# haltium_celldsp register map
Vendor: Nordic Semiconductor; Series: nRFHaltium; File version: 1
Registers are 32-bit, read-write, reset 0x0 unless marked. A register's access mark holds for its fields unless they carry their own. Offsets are from the block's base; [hi:lo] are bit positions; lines under a group give offsets from that group; {n}, {i} and the like mark numbered series.

## GLOBAL_TSGEN — GENERIC 0
Base 0xBF041000
Same registers: GENERIC2 0x45007000, GLOBAL_CAN 0x4F8D5000, GLOBAL_ETB 0xBF044000, GLOBAL_ETR 0xBF045000
0x00 TASKS_GENERICTASK wo — Generic event
  [0] TASKS_GENERICTASK
    1=Trigger task
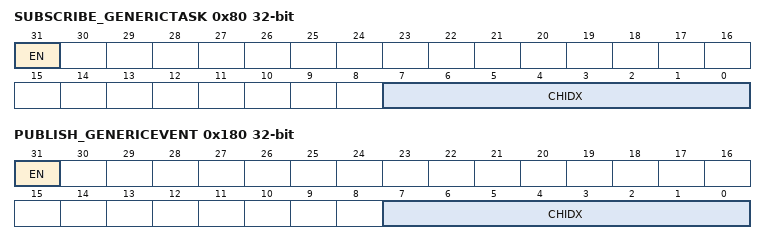
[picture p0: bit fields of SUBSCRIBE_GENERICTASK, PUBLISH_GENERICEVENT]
0x80 SUBSCRIBE_GENERICTASK — Subscribe configuration for task GENERICTASK
  [31] EN
    0=Disabled (Disable subscription); 1=Enabled (Enable subscription)
  [7:0] CHIDX — DPPI channel that task GENERICTASK will subscribe to
0x100 EVENTS_GENERICEVENT — Generic event
  [0] EVENTS_GENERICEVENT
    0=NotGenerated (Event not generated); 1=Generated (Event generated)
0x180 PUBLISH_GENERICEVENT — Publish configuration for event GENERICEVENT
  [31] EN
    0=Disabled (Disable publishing); 1=Enabled (Enable publishing)
  [7:0] CHIDX — DPPI channel that event GENERICEVENT will publish to
0x300 INTEN — Enable or disable interrupt
  [0] GENERICEVENT — Enable or disable interrupt for event GENERICEVENT
    0=Disabled; 1=Enabled
0x304 INTENSET — Enable interrupt
  [0] GENERICEVENT — Write '1' to enable interrupt for event GENERICEVENT
    on read: 0=Disabled (Read: Disabled); 1=Enabled (Read: Enabled) | on write: 1=Set (Enable)
0x308 INTENCLR — Disable interrupt
  [0] GENERICEVENT — Write '1' to disable interrupt for event GENERICEVENT
    on read: 0=Disabled (Read: Disabled); 1=Enabled (Read: Enabled) | on write: 1=Clear (Disable)

## RAMC00 — RAM Controller 0
Base 0x45004000
Same registers: RAMC10 0x45005000, RAMC20 0x45006000
0x300 INTEN — Enable or disable interrupt
0x304 INTENSET — Enable interrupt
0x308 INTENCLR — Disable interrupt
0x500 WAITSTATES — Waitstates for read.
  [2:0] WAITSTATES — Waitstates for read from RAM or ROM.
0x600 SECBASE — Base address for secure access area.
  [31:0] ADDR — Base address
0x604 SECENABLE — Enable secure access restrictions.
  [0] ENABLE — Enable secure access restrictions
    0=Disable (Secure access restrictions disabled); 1=Enable (Secure access restrictions enabled)

## DSPINTMAP — DSP interrupt mapper
Base 0x45008000
0x504 OFFSET reset 0x100000 — Address offset for IRQ destination address
0x508 ADDRESSINCREMENT reset 0x200 — Address increment for IRQ destination address
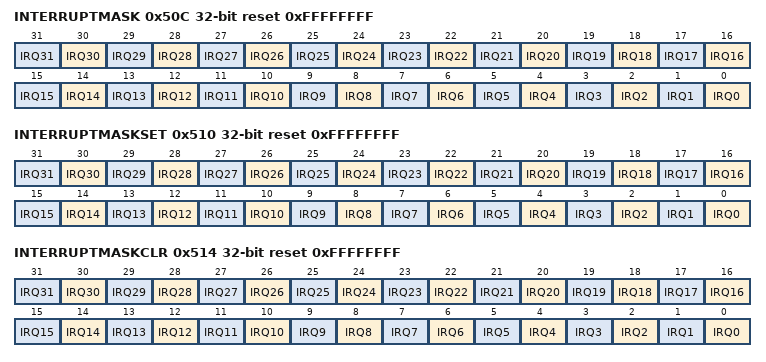
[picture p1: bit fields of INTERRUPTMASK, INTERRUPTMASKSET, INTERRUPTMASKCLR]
0x50C INTERRUPTMASK reset 0xFFFFFFFF — Write interrupt mask
  [all] fields
    0=Low (IRQ[i] is unmasked); 1=High (IRQ[i] is masked)
  [n] IRQ{n} (n=0..31) — Mask or unmask interrupt IRQ[i]
0x510 INTERRUPTMASKSET reset 0xFFFFFFFF write-1-sets — Set individual mask bits in interrupt mask
  [n] IRQ{n} (n=0..31) — Write '1' to mask IRQ[i]
    on read: 0=Low (Read: IRQ{n} is unmasked); 1=High (Read: IRQ{n} is masked) | on write: 1=Set (Write: writing a '1' sets the mask on; writing a '0' has no effect)
0x514 INTERRUPTMASKCLR reset 0xFFFFFFFF write-1-clears — Clear individual mask bits in interrupt mask
  [n] IRQ{n} (n=0..31) — Write '1' to unmask IRQ[i]
    on read: 0=Low (Read: IRQ{n} is unmasked); 1=High (Read: IRQ{n} is masked) | on write: 1=Clear (Write: writing a '1' sets the mask off; writing a '0' has no effect)
{0x518+4i} INTERRUPTPRIORITY[{i}] (i=0..31) — Description collection: Priority of interrupt IRQn
  [2:0] PRIORITY — Interrupt priority
    0=Highest priority; 7=Lowest priority
0xD00 INTERRUPTSTATUS ro — InterruptStatus indicates that an IRQ is sent to DSP, but not yet cleared

## PPIB0 — PPIB APB registers 0
Base 0x4500E000
Same registers: PPIB1 0x45016000
{0x0+4i} TASKS_SEND[{i}] (i=0..31) wo — Description collection: This task is unused, but the PPIB provides the SUBSCRIBE task to connect SEND [n] task.
  [0] TASKS_SEND — This task is unused, but the PPIB provides the SUBSCRIBE task to connect SEND [n] task.
    1=Trigger task
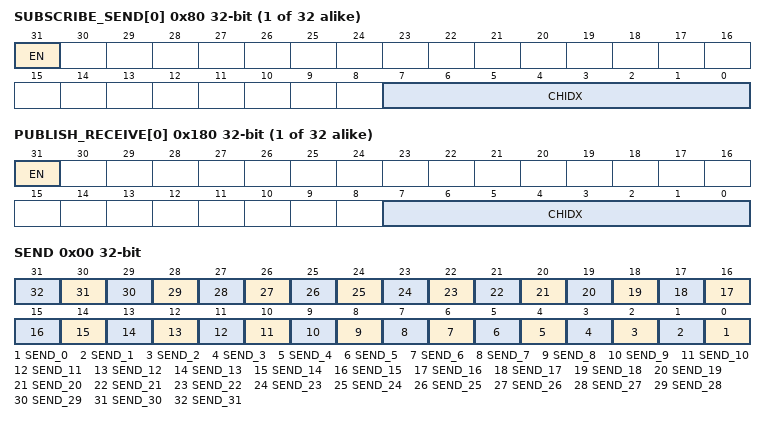
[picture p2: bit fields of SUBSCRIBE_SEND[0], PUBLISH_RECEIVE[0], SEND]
{0x80+4i} SUBSCRIBE_SEND[{i}] (i=0..31) — Description collection: Subscribe configuration for task SEND[n]
  [31] EN
    0=Disabled (Disable subscription); 1=Enabled (Enable subscription)
  [7:0] CHIDX — DPPI channel that task SEND[n] will subscribe to
{0x100+4i} EVENTS_RECEIVE[{i}] (i=0..31) — Description collection: This event is unused, but the PPIB provides the PUBLISH event to connect RECEIVE [n] event.
  [0] EVENTS_RECEIVE — This event is unused, but the PPIB provides the PUBLISH event to connect RECEIVE [n] event.
    0=NotGenerated (Event not generated); 1=Generated (Event generated)
{0x180+4i} PUBLISH_RECEIVE[{i}] (i=0..31) — Description collection: Publish configuration for event RECEIVE[n]
  [31] EN
    0=Disabled (Disable publishing); 1=Enabled (Enable publishing)
  [7:0] CHIDX — DPPI channel that event RECEIVE[n] will publish to
0x400 OVERFLOW group — Unspecified
  0x00 SEND — The task overflow for SEND tasks using SUBSCRIBE_SEND. Write 0 to clear.
    [all] fields
      1=Overflow (Task overflow is happened.); 0=NoOverflow (Task overflow is not happened.)
    [n] SEND_{n} (n=0..31) — The status for tasks overflow at SUBSCRIBE_SEND[{n}].
